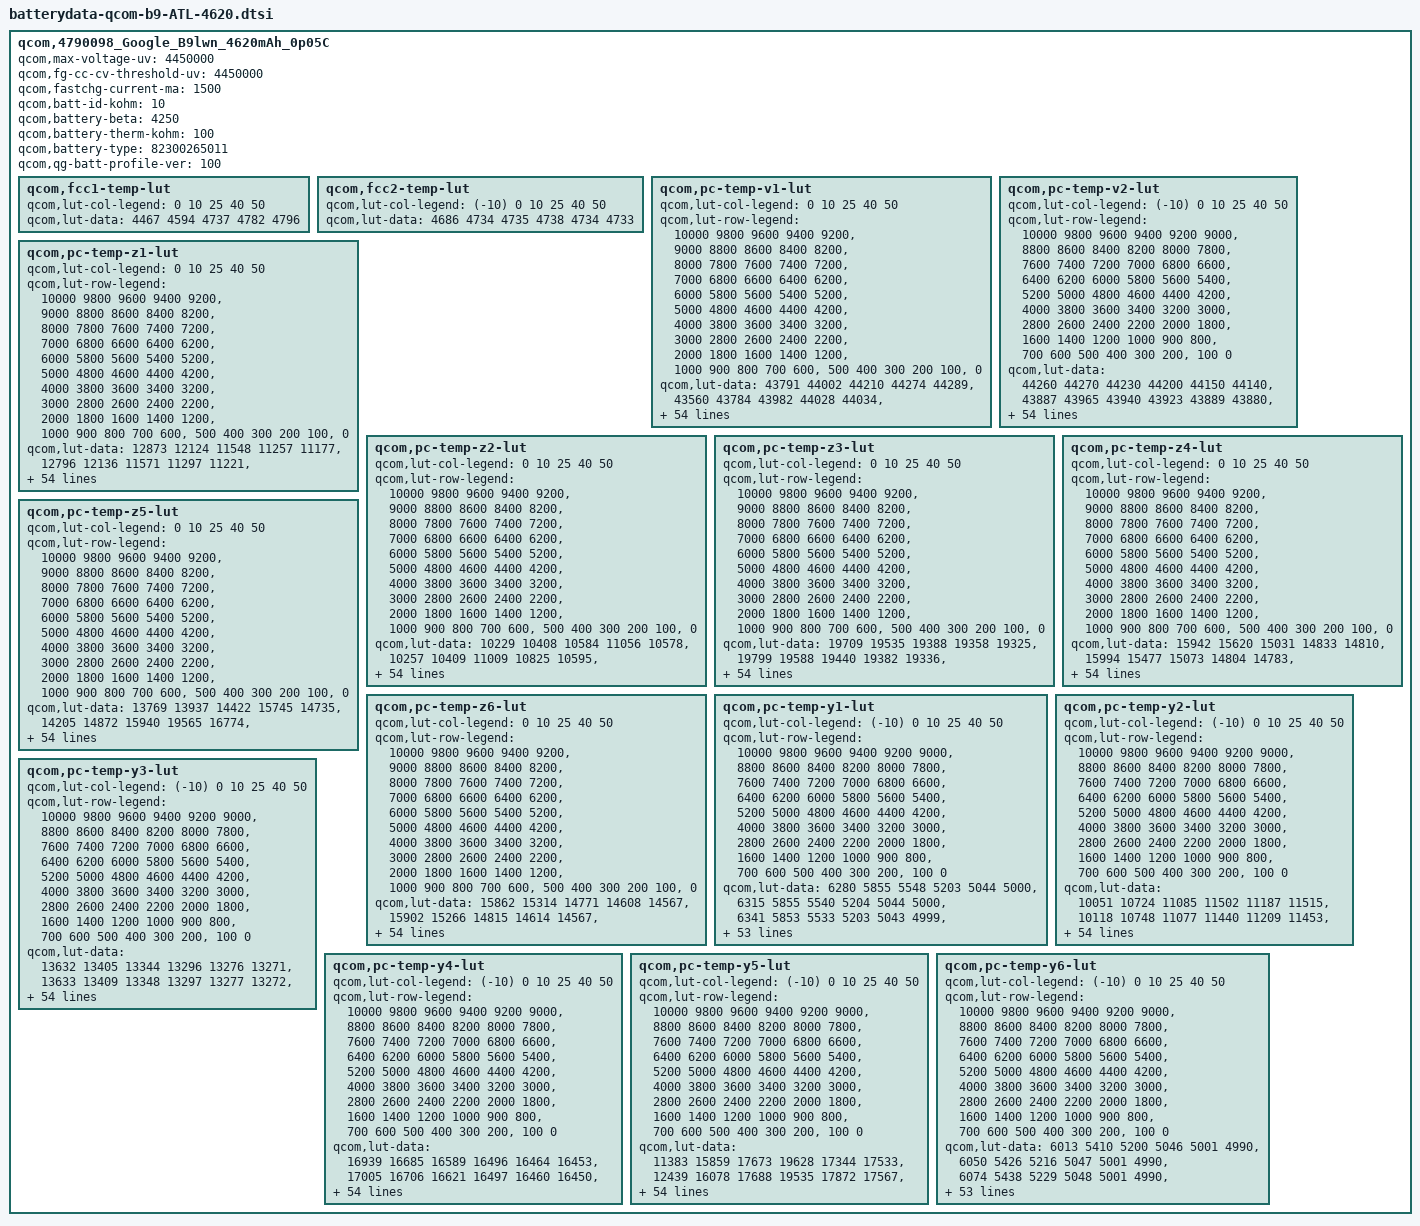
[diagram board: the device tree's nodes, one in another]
// SPDX-License-Identifier: GPL-2.0
qcom,4790098_Google_B9lwn_4620mAh_0p05C {
	/* 4790098_Google_B9lwn_4620mAh_0p05C_Oct30th2020 */
	qcom,max-voltage-uv = <4450000>;
	qcom,fg-cc-cv-threshold-uv = <4450000>;
	qcom,fastchg-current-ma = <1500>;
	qcom,batt-id-kohm = <10>;
	qcom,battery-beta = <4250>;
	qcom,battery-therm-kohm = <100>;
	qcom,battery-type = "82300265011";
	qcom,qg-batt-profile-ver = <100>;

	qcom,fcc1-temp-lut {
		qcom,lut-col-legend = <0 10 25 40 50>;
		qcom,lut-data = <4467 4594 4737 4782 4796>;
	};

	qcom,fcc2-temp-lut {
		qcom,lut-col-legend = <(-10) 0 10 25 40 50>;
		qcom,lut-data = <4686 4734 4735 4738 4734 4733>;
	};

	qcom,pc-temp-v1-lut {
		qcom,lut-col-legend = <0 10 25 40 50>;
		qcom,lut-row-legend = <10000 9800 9600 9400 9200>,
			<9000 8800 8600 8400 8200>,
			<8000 7800 7600 7400 7200>,
			<7000 6800 6600 6400 6200>,
			<6000 5800 5600 5400 5200>,
			<5000 4800 4600 4400 4200>,
			<4000 3800 3600 3400 3200>,
			<3000 2800 2600 2400 2200>,
			<2000 1800 1600 1400 1200>,
			<1000 900 800 700 600>,
			<500 400 300 200 100>,
			<0>;
		qcom,lut-data = <43791 44002 44210 44274 44289>,
			<43560 43784 43982 44028 44034>,
			<43330 43561 43754 43811 43813>,
			<43100 43333 43543 43600 43602>,
			<42867 43100 43323 43382 43390>,
			<42630 42864 43091 43154 43167>,
			<42396 42626 42854 42918 42936>,
			<42166 42387 42611 42680 42701>,
			<41939 42152 42363 42438 42461>,
			<41718 41919 42122 42196 42219>,
			<41503 41691 41886 41955 41980>,
			<41293 41467 41654 41716 41742>,
			<41089 41249 41427 41485 41510>,
			<40892 41045 41204 41259 41281>,
			<40694 40851 40988 41039 41059>,
			<40489 40657 40778 40824 40843>,
			<40290 40455 40577 40616 40633>,
			<40115 40260 40386 40418 40435>,
			<39957 40089 40202 40229 40246>,
			<39806 39937 40031 40050 40064>,
			<39660 39771 39870 39886 39898>,
			<39515 39576 39676 39709 39722>,
			<39357 39372 39396 39474 39497>,
			<39179 39164 39137 39224 39252>,
			<39007 38946 38993 39044 39064>,
			<38854 38794 38887 38904 38916>,
			<38714 38712 38785 38782 38787>,
			<38609 38648 38682 38671 38674>,
			<38530 38579 38588 38571 38571>,
			<38466 38510 38503 38477 38474>,
			<38415 38446 38426 38390 38383>,
			<38371 38384 38356 38312 38300>,
			<38332 38328 38294 38242 38224>,
			<38294 38278 38237 38178 38155>,
			<38259 38235 38187 38124 38093>,
			<38225 38193 38140 38074 38036>,
			<38196 38156 38093 38018 37971>,
			<38158 38117 38048 37957 37896>,
			<38096 38054 37989 37887 37813>,
			<38007 37957 37899 37802 37724>,
			<37904 37845 37790 37702 37624>,
			<37779 37722 37672 37587 37510>,
			<37633 37581 37536 37451 37376>,
			<37460 37410 37370 37291 37219>,
			<37338 37253 37209 37137 37068>,
			<37231 37149 37100 37038 36975>,
			<37191 37117 37077 37012 36952>,
			<37158 37096 37055 36996 36935>,
			<37124 37069 37038 36980 36918>,
			<37076 37031 37001 36939 36874>,
			<36905 36844 36806 36720 36631>,
			<36470 36417 36387 36297 36203>,
			<35896 35845 35822 35732 35637>,
			<35110 35059 35053 34965 34870>,
			<33811 33795 33864 33790 33691>,
			<30000 30000 30000 30000 30000>;
	};

	qcom,pc-temp-v2-lut {
		qcom,lut-col-legend = <(-10) 0 10 25 40 50>;
		qcom,lut-row-legend = <10000 9800 9600 9400 9200 9000>,
			<8800 8600 8400 8200 8000 7800>,
			<7600 7400 7200 7000 6800 6600>,
			<6400 6200 6000 5800 5600 5400>,
			<5200 5000 4800 4600 4400 4200>,
			<4000 3800 3600 3400 3200 3000>,
			<2800 2600 2400 2200 2000 1800>,
			<1600 1400 1200 1000 900 800>,
			<700 600 500 400 300 200>,
			<100 0>;
		qcom,lut-data = <44260 44270 44230 44200 44150 44140>,
			<43887 43965 43940 43923 43889 43880>,
			<43554 43685 43671 43662 43639 43632>,
			<43270 43433 43423 43421 43405 43398>,
			<43030 43209 43199 43199 43184 43178>,
			<42789 42981 42970 42972 42959 42955>,
			<42521 42737 42728 42734 42724 42721>,
			<42258 42490 42484 42492 42484 42483>,
			<42036 42244 42239 42251 42246 42246>,
			<41843 41999 41994 42010 42006 42008>,
			<41633 41765 41754 41773 41771 41774>,
			<41373 41547 41518 41541 41538 41543>,
			<41109 41332 41290 41314 41310 41316>,
			<40896 41110 41069 41090 41087 41094>,
			<40713 40887 40856 40870 40868 40876>,
			<40483 40664 40656 40660 40659 40666>,
			<40125 40444 40473 40457 40457 40462>,
			<39762 40217 40279 40262 40262 40265>,
			<39513 39963 40049 40082 40080 40083>,
			<39313 39699 39801 39905 39902 39904>,
			<39118 39469 39566 39698 39706 39713>,
			<38918 39265 39337 39453 39489 39506>,
			<38735 39078 39130 39222 39276 39299>,
			<38574 38904 38947 39020 39066 39088>,
			<38430 38743 38784 38840 38872 38888>,
			<38324 38592 38638 38693 38724 38739>,
			<38248 38451 38507 38570 38605 38619>,
			<38182 38319 38388 38460 38497 38510>,
			<38117 38186 38280 38360 38397 38408>,
			<38057 38074 38178 38266 38304 38313>,
			<37999 38006 38076 38180 38219 38227>,
			<37944 37957 37974 38099 38141 38147>,
			<37888 37909 37901 38025 38068 38073>,
			<37827 37861 37852 37959 38004 38008>,
			<37764 37814 37810 37895 37937 37938>,
			<37698 37765 37771 37829 37852 37841>,
			<37630 37713 37734 37763 37758 37723>,
			<37557 37653 37689 37688 37661 37614>,
			<37474 37583 37633 37605 37560 37511>,
			<37388 37505 37564 37519 37463 37414>,
			<37301 37416 37471 37437 37378 37328>,
			<37212 37312 37354 37345 37289 37238>,
			<37128 37185 37207 37219 37169 37116>,
			<37047 37031 37039 37074 37032 36977>,
			<36965 36888 36875 36926 36892 36842>,
			<36865 36797 36780 36872 36851 36804>,
			<36812 36762 36751 36854 36843 36794>,
			<36755 36731 36714 36837 36827 36779>,
			<36691 36695 36671 36807 36804 36756>,
			<36604 36637 36598 36737 36737 36680>,
			<36447 36464 36402 36515 36502 36420>,
			<36125 36017 35971 36052 36031 35942>,
			<35589 35358 35350 35435 35414 35327>,
			<34792 34428 34488 34597 34570 34476>,
			<33485 32895 33183 33372 33352 33229>,
			<31370 29553 29515 29517 29516 29515>;
	};

	qcom,pc-temp-z1-lut {
		qcom,lut-col-legend = <0 10 25 40 50>;
		qcom,lut-row-legend = <10000 9800 9600 9400 9200>,
			<9000 8800 8600 8400 8200>,
			<8000 7800 7600 7400 7200>,
			<7000 6800 6600 6400 6200>,
			<6000 5800 5600 5400 5200>,
			<5000 4800 4600 4400 4200>,
			<4000 3800 3600 3400 3200>,
			<3000 2800 2600 2400 2200>,
			<2000 1800 1600 1400 1200>,
			<1000 900 800 700 600>,
			<500 400 300 200 100>,
			<0>;
		qcom,lut-data = <12873 12124 11548 11257 11177>,
			<12796 12136 11571 11297 11221>,
			<12800 12142 11567 11298 11227>,
			<12806 12140 11567 11298 11229>,
			<12807 12133 11566 11298 11231>,
			<12801 12124 11563 11298 11231>,
			<12794 12114 11559 11296 11231>,
			<12788 12104 11555 11295 11230>,
			<12781 12104 11550 11293 11229>,
			<12773 12107 11547 11292 11228>,
			<12763 12108 11544 11291 11228>,
			<12756 12103 11543 11291 11228>,
			<12756 12097 11543 11291 11228>,
			<12757 12097 11543 11291 11229>,
			<12760 12098 11543 11292 11230>,
			<12768 12099 11542 11293 11231>,
			<12778 12096 11542 11294 11233>,
			<12780 12092 11543 11295 11234>,
			<12782 12093 11544 11296 11236>,
			<12782 12098 11546 11298 11238>,
			<12784 12103 11549 11299 11239>,
			<12787 12111 11552 11300 11241>,
			<12790 12118 11557 11303 11243>,
			<12799 12121 11562 11306 11245>,
			<12806 12123 11566 11310 11248>,
			<12806 12125 11570 11313 11252>,
			<12804 12128 11574 11317 11255>,
			<12805 12130 11579 11320 11258>,
			<12807 12132 11584 11324 11260>,
			<12810 12133 11588 11328 11263>,
			<12813 12135 11593 11331 11265>,
			<12817 12139 11597 11334 11268>,
			<12822 12143 11599 11336 11271>,
			<12835 12147 11602 11340 11273>,
			<12850 12150 11607 11343 11276>,
			<12856 12155 11613 11347 11278>,
			<12859 12163 11618 11350 11281>,
			<12860 12172 11623 11352 11284>,
			<12863 12177 11627 11355 11286>,
			<12868 12181 11632 11358 11288>,
			<12872 12184 11637 11362 11290>,
			<12876 12186 11641 11365 11292>,
			<12878 12188 11646 11368 11294>,
			<12877 12206 11650 11371 11296>,
			<12888 12210 11656 11374 11299>,
			<12884 12212 11664 11376 11300>,
			<12897 12204 11669 11376 11301>,
			<12890 12210 11670 11376 11300>,
			<12881 12212 11666 11377 11301>,
			<12897 12208 11668 11380 11302>,
			<12898 12219 11676 11385 11306>,
			<12943 12229 11687 11392 11313>,
			<12966 12258 11704 11401 11320>,
			<12979 12280 11722 11415 11332>,
			<12979 12280 11722 11415 11332>,
			<12979 12280 11722 11415 11332>;
	};

	qcom,pc-temp-z2-lut {
		qcom,lut-col-legend = <0 10 25 40 50>;
		qcom,lut-row-legend = <10000 9800 9600 9400 9200>,
			<9000 8800 8600 8400 8200>,
			<8000 7800 7600 7400 7200>,
			<7000 6800 6600 6400 6200>,
			<6000 5800 5600 5400 5200>,
			<5000 4800 4600 4400 4200>,
			<4000 3800 3600 3400 3200>,
			<3000 2800 2600 2400 2200>,
			<2000 1800 1600 1400 1200>,
			<1000 900 800 700 600>,
			<500 400 300 200 100>,
			<0>;
		qcom,lut-data = <10229 10408 10584 11056 10578>,
			<10257 10409 11009 10825 10595>,
			<10246 10399 10644 10790 10784>,
			<10231 10378 10614 10757 10774>,
			<10227 10338 10579 10717 10750>,
			<10228 10304 10529 10692 10700>,
			<10229 10277 10496 10672 10618>,
			<10221 10259 10506 10666 10578>,
			<10208 10265 10532 10666 10527>,
			<10207 10290 10583 10665 10487>,
			<10248 10310 10763 10660 10498>,
			<10287 10320 10877 10653 10526>,
			<10271 10331 10868 10624 10532>,
			<10218 10381 10856 10549 10538>,
			<10187 10492 10861 10515 10543>,
			<10179 10539 10879 10515 10549>,
			<10174 10481 10897 10520 10559>,
			<10179 10415 10923 10538 10568>,
			<10201 10410 10945 10572 10579>,
			<10222 10416 10879 10583 10591>,
			<10233 10421 10683 10581 10600>,
			<10242 10436 10608 10580 10613>,
			<10252 10451 10625 10612 10666>,
			<10263 10447 10640 10680 10745>,
			<10272 10423 10636 10760 10760>,
			<10279 10410 10629 10871 10746>,
			<10284 10420 10637 10918 10723>,
			<10290 10433 10668 10805 10607>,
			<10298 10439 10690 10669 10472>,
			<10306 10441 10663 10646 10458>,
			<10311 10444 10614 10638 10462>,
			<10316 10446 10606 10639 10468>,
			<10321 10449 10615 10660 10485>,
			<10328 10455 10627 10681 10510>,
			<10336 10467 10648 10689 10551>,
			<10344 10477 10673 10701 10613>,
			<10351 10482 10687 10735 10675>,
			<10359 10487 10701 10843 10747>,
			<10370 10499 10717 10904 10796>,
			<10380 10524 10760 10892 10819>,
			<10384 10538 10800 10876 10832>,
			<10385 10528 10795 10883 10829>,
			<10388 10520 10781 10906 10810>,
			<10406 10525 10786 10915 10784>,
			<10093 10580 10798 10900 10763>,
			<10065 10625 10798 10802 10772>,
			<10185 10615 10774 10771 10782>,
			<10204 10687 10748 10788 10749>,
			<10249 10688 10751 10766 10771>,
			<10228 10735 10787 10859 10915>,
			<10184 10812 10937 10783 10647>,
			<10040 10854 10929 10644 10484>,
			<9845 10811 10955 10586 10441>,
			<9628 10607 10892 10519 10441>,
			<9628 10607 10892 10519 10441>,
			<9628 10607 10892 10519 10441>;
	};

	qcom,pc-temp-z3-lut {
		qcom,lut-col-legend = <0 10 25 40 50>;
		qcom,lut-row-legend = <10000 9800 9600 9400 9200>,
			<9000 8800 8600 8400 8200>,
			<8000 7800 7600 7400 7200>,
			<7000 6800 6600 6400 6200>,
			<6000 5800 5600 5400 5200>,
			<5000 4800 4600 4400 4200>,
			<4000 3800 3600 3400 3200>,
			<3000 2800 2600 2400 2200>,
			<2000 1800 1600 1400 1200>,
			<1000 900 800 700 600>,
			<500 400 300 200 100>,
			<0>;
		qcom,lut-data = <19709 19535 19388 19358 19325>,
			<19799 19588 19440 19382 19336>,
			<19825 19626 19483 19392 19371>,
			<19839 19645 19492 19403 19381>,
			<19838 19659 19494 19407 19385>,
			<19828 19662 19490 19405 19383>,
			<19817 19658 19484 19401 19375>,
			<19808 19650 19478 19396 19369>,
			<19800 19639 19472 19389 19364>,
			<19796 19620 19469 19384 19360>,
			<19801 19606 19469 19382 19357>,
			<19805 19599 19467 19380 19354>,
			<19792 19593 19459 19375 19351>,
			<19767 19590 19448 19363 19346>,
			<19756 19585 19444 19358 19344>,
			<19763 19582 19442 19357 19343>,
			<19771 19576 19440 19356 19342>,
			<19767 19570 19437 19354 19339>,
			<19744 19565 19434 19352 19333>,
			<19731 19561 19428 19350 19330>,
			<19731 19559 19418 19349 19328>,
			<19732 19568 19415 19348 19327>,
			<19735 19579 19433 19349 19328>,
			<19753 19583 19450 19352 19332>,
			<19767 19586 19441 19360 19341>,
			<19767 19586 19418 19382 19363>,
			<19766 19578 19414 19393 19376>,
			<19765 19568 19439 19393 19369>,
			<19762 19568 19458 19392 19360>,
			<19756 19572 19459 19390 19356>,
			<19750 19575 19459 19386 19354>,
			<19742 19576 19457 19382 19351>,
			<19735 19577 19450 19377 19347>,
			<19730 19575 19442 19372 19343>,
			<19726 19570 19438 19365 19338>,
			<19721 19564 19434 19359 19334>,
			<19714 19561 19431 19357 19333>,
			<19708 19557 19429 19357 19333>,
			<19702 19552 19425 19357 19333>,
			<19695 19546 19420 19354 19335>,
			<19688 19540 19416 19350 19336>,
			<19681 19535 19412 19350 19336>,
			<19671 19530 19408 19351 19334>,
			<19657 19524 19406 19351 19334>,
			<19352 19500 19400 19350 19335>,
			<19264 19479 19394 19341 19328>,
			<19263 19474 19385 19340 19323>,
			<19262 19447 19387 19336 19321>,
			<19262 19445 19379 19331 19317>,
			<19262 19435 19373 19326 19309>,
			<19262 19417 19343 19339 19335>,
			<19263 19375 19346 19346 19340>,
			<19265 19337 19340 19349 19343>,
			<19272 19340 19334 19351 19332>,
			<19272 19340 19334 19351 19332>,
			<19272 19340 19334 19351 19332>;
	};

	qcom,pc-temp-z4-lut {
		qcom,lut-col-legend = <0 10 25 40 50>;
		qcom,lut-row-legend = <10000 9800 9600 9400 9200>,
			<9000 8800 8600 8400 8200>,
			<8000 7800 7600 7400 7200>,
			<7000 6800 6600 6400 6200>,
			<6000 5800 5600 5400 5200>,
			<5000 4800 4600 4400 4200>,
			<4000 3800 3600 3400 3200>,
			<3000 2800 2600 2400 2200>,
			<2000 1800 1600 1400 1200>,
			<1000 900 800 700 600>,
			<500 400 300 200 100>,
			<0>;
		qcom,lut-data = <15942 15620 15031 14833 14810>,
			<15994 15477 15073 14804 14783>,
			<15856 15348 15121 14906 14835>,
			<15631 15233 15024 14873 14815>,
			<15485 15129 14950 14832 14786>,
			<15381 15047 14900 14805 14769>,
			<15293 14982 14861 14782 14756>,
			<15219 14932 14834 14769 14747>,
			<15154 14898 14814 14762 14741>,
			<15085 14873 14793 14755 14736>,
			<14997 14855 14769 14744 14729>,
			<14933 14841 14753 14734 14722>,
			<14923 14830 14747 14729 14715>,
			<14923 14813 14742 14726 14709>,
			<14920 14791 14735 14722 14702>,
			<14910 14783 14725 14713 14693>,
			<14898 14792 14716 14702 14684>,
			<14887 14802 14710 14694 14679>,
			<14878 14796 14706 14687 14674>,
			<14867 14775 14706 14684 14671>,
			<14850 14765 14713 14682 14669>,
			<14834 14786 14730 14682 14668>,
			<14833 14824 14823 14738 14708>,
			<14855 14876 14908 14829 14786>,
			<14884 14952 14912 14838 14798>,
			<14917 14985 14912 14807 14766>,
			<14953 14965 14905 14778 14740>,
			<14964 14930 14861 14759 14731>,
			<14957 14903 14816 14743 14725>,
			<14947 14877 14794 14730 14716>,
			<14935 14858 14779 14719 14705>,
			<14919 14845 14771 14712 14696>,
			<14904 14835 14766 14705 14689>,
			<14891 14829 14763 14702 14684>,
			<14879 14825 14761 14702 14682>,
			<14866 14821 14760 14702 14681>,
			<14853 14815 14761 14704 14683>,
			<14842 14810 14764 14716 14700>,
			<14835 14810 14768 14726 14711>,
			<14830 14811 14774 14731 14710>,
			<14823 14811 14779 14735 14709>,
			<14811 14796 14772 14731 14705>,
			<14798 14775 14755 14718 14698>,
			<14783 14763 14747 14717 14700>,
			<15008 14736 14732 14715 14700>,
			<15074 14713 14704 14698 14686>,
			<15070 14706 14695 14687 14680>,
			<15059 14719 14675 14670 14661>,
			<15052 14708 14664 14653 14645>,
			<15043 14711 14665 14654 14647>,
			<15040 14742 14720 14666 14648>,
			<15065 14798 14722 14664 14649>,
			<15079 14848 14727 14662 14646>,
			<15095 14855 14735 14659 14655>,
			<15095 14855 14735 14659 14655>,
			<15095 14855 14735 14659 14655>;
	};

	qcom,pc-temp-z5-lut {
		qcom,lut-col-legend = <0 10 25 40 50>;
		qcom,lut-row-legend = <10000 9800 9600 9400 9200>,
			<9000 8800 8600 8400 8200>,
			<8000 7800 7600 7400 7200>,
			<7000 6800 6600 6400 6200>,
			<6000 5800 5600 5400 5200>,
			<5000 4800 4600 4400 4200>,
			<4000 3800 3600 3400 3200>,
			<3000 2800 2600 2400 2200>,
			<2000 1800 1600 1400 1200>,
			<1000 900 800 700 600>,
			<500 400 300 200 100>,
			<0>;
		qcom,lut-data = <13769 13937 14422 15745 14735>,
			<14205 14872 15940 19565 16774>,
			<14536 15721 16960 17400 19051>,
			<14820 16480 17521 17969 19995>,
			<15074 17175 17860 18699 20665>,
			<15292 17791 18020 19247 20802>,
			<15522 18365 18199 19711 20611>,
			<15775 18882 18683 19752 20520>,
			<16064 19301 19433 19425 20215>,
			<16552 19654 20066 19212 19942>,
			<17869 20037 20971 19566 19979>,
			<18956 20560 21433 20064 20073>,
			<18916 21053 21107 19848 20079>,
			<18614 21354 20676 18841 19994>,
			<18532 21662 20801 18415 20052>,
			<19891 21970 21710 18923 20906>,
			<21491 22261 22603 19670 21848>,
			<21535 22641 23303 20269 21752>,
			<20884 23364 23874 20887 21230>,
			<20497 24796 23954 21506 21085>,
			<21485 26775 23577 22226 21659>,
			<23767 30962 24094 22617 22158>,
			<26985 34842 28694 21626 20740>,
			<33112 34888 32871 19894 18012>,
			<37370 33324 29352 19185 17583>,
			<37343 31393 20912 18780 18564>,
			<36911 28067 18577 18646 19155>,
			<36289 24975 19919 19190 18977>,
			<34974 24775 21742 20178 18744>,
			<33411 25593 23631 21308 19013>,
			<32110 26690 25688 22763 20146>,
			<30838 28621 27255 24174 21264>,
			<30319 30763 28500 25654 22243>,
			<30403 31888 29674 26771 23214>,
			<30544 32725 31155 27349 24337>,
			<30639 33187 32333 27742 25400>,
			<30680 33428 32376 27800 25521>,
			<30687 33605 31956 27577 24819>,
			<30989 33408 31266 27176 24086>,
			<31566 32385 29039 24979 23611>,
			<31628 31583 26728 22403 23162>,
			<30489 31141 26062 22280 22692>,
			<29377 30707 25788 22680 22136>,
			<28675 29581 24921 22288 21243>,
			<15248 28263 24708 21295 20815>,
			<11406 25940 26217 20665 19721>,
			<11359 24957 24158 21492 19074>,
			<11313 19456 26643 22131 20636>,
			<11300 19479 25029 24107 23792>,
			<11304 18406 23592 22828 20600>,
			<11335 16640 15872 20107 23712>,
			<11275 14017 15213 20168 23285>,
			<11209 12528 14458 20074 23609>,
			<11246 12446 13876 19838 18287>,
			<11246 12446 13876 19838 18287>,
			<11246 12446 13876 19838 18287>;
	};

	qcom,pc-temp-z6-lut {
		qcom,lut-col-legend = <0 10 25 40 50>;
		qcom,lut-row-legend = <10000 9800 9600 9400 9200>,
			<9000 8800 8600 8400 8200>,
			<8000 7800 7600 7400 7200>,
			<7000 6800 6600 6400 6200>,
			<6000 5800 5600 5400 5200>,
			<5000 4800 4600 4400 4200>,
			<4000 3800 3600 3400 3200>,
			<3000 2800 2600 2400 2200>,
			<2000 1800 1600 1400 1200>,
			<1000 900 800 700 600>,
			<500 400 300 200 100>,
			<0>;
		qcom,lut-data = <15862 15314 14771 14608 14567>,
			<15902 15266 14815 14614 14567>,
			<15835 15218 14855 14661 14609>,
			<15722 15170 14819 14652 14604>,
			<15640 15122 14787 14639 14597>,
			<15574 15079 14762 14627 14589>,
			<15516 15040 14741 14615 14579>,
			<15467 15007 14725 14606 14572>,
			<15425 14980 14712 14599 14566>,
			<15385 14957 14700 14592 14561>,
			<15345 14941 14690 14587 14557>,
			<15314 14930 14682 14581 14552>,
			<15296 14921 14674 14575 14547>,
			<15284 14910 14667 14568 14542>,
			<15279 14899 14660 14563 14537>,
			<15279 14894 14655 14558 14533>,
			<15278 14894 14650 14553 14529>,
			<15274 14893 14645 14549 14525>,
			<15260 14889 14642 14545 14520>,
			<15249 14878 14641 14543 14517>,
			<15244 14873 14640 14542 14515>,
			<15241 14888 14643 14541 14514>,
			<15244 14913 14692 14567 14534>,
			<15265 14941 14741 14609 14571>,
			<15290 14978 14739 14616 14579>,
			<15309 14993 14730 14614 14578>,
			<15326 14981 14723 14612 14576>,
			<15331 14964 14717 14605 14570>,
			<15329 14953 14711 14597 14562>,
			<15326 14945 14705 14590 14556>,
			<15321 14940 14699 14584 14550>,
			<15313 14937 14693 14579 14545>,
			<15307 14935 14688 14574 14540>,
			<15301 14933 14684 14569 14535>,
			<15297 14930 14682 14566 14532>,
			<15293 14928 14681 14563 14529>,
			<15289 14927 14681 14563 14530>,
			<15287 14926 14682 14569 14537>,
			<15288 14927 14682 14573 14542>,
			<15291 14928 14683 14574 14543>,
			<15291 14929 14685 14574 14543>,
			<15291 14923 14682 14572 14542>,
			<15289 14916 14674 14568 14538>,
			<15284 14914 14671 14569 14540>,
			<15244 14900 14664 14568 14541>,
			<15236 14885 14651 14555 14531>,
			<15236 14881 14644 14551 14525>,
			<15233 14875 14636 14541 14517>,
			<15234 14872 14628 14530 14507>,
			<15238 14872 14627 14530 14504>,
			<15246 14883 14638 14543 14519>,
			<15272 14893 14644 14547 14524>,
			<15297 14905 14647 14550 14527>,
			<15337 14927 14654 14553 14528>,
			<15337 14927 14654 14553 14528>,
			<15337 14927 14654 14553 14528>;
	};

	qcom,pc-temp-y1-lut {
		qcom,lut-col-legend = <(-10) 0 10 25 40 50>;
		qcom,lut-row-legend = <10000 9800 9600 9400 9200 9000>,
			<8800 8600 8400 8200 8000 7800>,
			<7600 7400 7200 7000 6800 6600>,
			<6400 6200 6000 5800 5600 5400>,
			<5200 5000 4800 4600 4400 4200>,
			<4000 3800 3600 3400 3200 3000>,
			<2800 2600 2400 2200 2000 1800>,
			<1600 1400 1200 1000 900 800>,
			<700 600 500 400 300 200>,
			<100 0>;
		qcom,lut-data = <6280 5855 5548 5203 5044 5000>,
			<6315 5855 5540 5204 5044 5000>,
			<6341 5853 5533 5203 5043 4999>,
			<6359 5851 5527 5201 5042 4998>,
			<6369 5849 5522 5200 5041 4997>,
			<6372 5849 5521 5197 5040 4996>,
			<6362 5850 5523 5194 5038 4995>,
			<6349 5851 5525 5191 5036 4994>,
			<6350 5849 5524 5188 5035 4994>,
			<6359 5843 5517 5186 5035 4994>,
			<6363 5841 5512 5184 5035 4994>,
			<6363 5840 5507 5181 5033 4994>,
			<6362 5840 5504 5180 5032 4994>,
			<6362 5843 5503 5179 5031 4994>,
			<6365 5850 5503 5179 5031 4994>,
			<6366 5854 5504 5179 5031 4994>,
			<6360 5857 5506 5179 5031 4994>,
			<6353 5859 5509 5179 5032 4995>,
			<6352 5863 5510 5180 5032 4995>,
			<6352 5869 5510 5181 5033 4996>,
			<6354 5868 5512 5183 5034 4997>,
			<6367 5862 5516 5186 5035 4998>,
			<6380 5858 5518 5189 5037 4999>,
			<6380 5860 5519 5192 5037 5000>,
			<6376 5863 5521 5195 5038 5001>,
			<6374 5864 5522 5197 5040 5003>,
			<6367 5865 5523 5200 5042 5003>,
			<6362 5865 5524 5202 5045 5005>,
			<6365 5867 5526 5205 5047 5006>,
			<6368 5869 5529 5209 5049 5008>,
			<6367 5868 5531 5212 5051 5010>,
			<6356 5866 5533 5215 5052 5012>,
			<6349 5865 5535 5219 5055 5014>,
			<6350 5866 5536 5223 5058 5016>,
			<6352 5868 5538 5227 5061 5018>,
			<6359 5874 5541 5230 5063 5019>,
			<6380 5884 5544 5233 5066 5020>,
			<6392 5885 5548 5236 5067 5021>,
			<6382 5877 5553 5240 5068 5023>,
			<6367 5870 5556 5242 5069 5024>,
			<6365 5871 5555 5243 5071 5025>,
			<6366 5872 5554 5244 5072 5025>,
			<6376 5883 5552 5249 5073 5027>,
			<6388 5890 5554 5253 5075 5028>,
			<6367 5905 5564 5257 5077 5030>,
			<6375 5895 5569 5265 5079 5031>,
			<6398 5906 5566 5263 5080 5032>,
			<6427 5904 5567 5264 5081 5032>,
			<6447 5918 5564 5267 5081 5033>,
			<6512 5931 5568 5271 5081 5032>,
			<6555 5936 5575 5280 5082 5034>,
			<6628 5980 5585 5289 5087 5038>,
			<6755 6051 5618 5296 5092 5042>,
			<6815 6277 5660 5314 5100 5048>,
			<6815 6277 5660 5314 5100 5048>,
			<6815 6277 5660 5314 5100 5048>;
	};

	qcom,pc-temp-y2-lut {
		qcom,lut-col-legend = <(-10) 0 10 25 40 50>;
		qcom,lut-row-legend = <10000 9800 9600 9400 9200 9000>,
			<8800 8600 8400 8200 8000 7800>,
			<7600 7400 7200 7000 6800 6600>,
			<6400 6200 6000 5800 5600 5400>,
			<5200 5000 4800 4600 4400 4200>,
			<4000 3800 3600 3400 3200 3000>,
			<2800 2600 2400 2200 2000 1800>,
			<1600 1400 1200 1000 900 800>,
			<700 600 500 400 300 200>,
			<100 0>;
		qcom,lut-data = <10051 10724 11085 11502 11187 11515>,
			<10118 10748 11077 11440 11209 11453>,
			<10195 10772 11066 11374 11222 11360>,
			<10272 10792 11052 11312 11228 11262>,
			<10334 10806 11036 11261 11229 11182>,
			<10372 10811 11022 11226 11226 11146>,
			<10386 10805 11005 11203 11174 11139>,
			<10398 10798 10989 11187 11113 11134>,
			<10461 10800 10974 11180 11109 11117>,
			<10627 10809 10959 11175 11119 11078>,
			<10706 10813 10955 11173 11133 11059>,
			<10662 10809 10968 11175 11169 11062>,
			<10611 10805 10988 11181 11205 11067>,
			<10628 10867 11012 11197 11209 11073>,
			<10697 11009 11043 11230 11205 11085>,
			<10704 11047 11081 11266 11214 11089>,
			<10227 11014 11134 11304 11266 11092>,
			<9729 10988 11178 11345 11336 11105>,
			<9692 11008 11198 11398 11418 11179>,
			<9688 11048 11212 11451 11510 11316>,
			<9683 11073 11220 11454 11568 11434>,
			<9678 11091 11226 11420 11614 11564>,
			<9674 11103 11231 11399 11633 11624>,
			<9672 11111 11241 11396 11547 11530>,
			<9671 11115 11253 11395 11428 11403>,
			<9670 11101 11267 11405 11424 11390>,
			<9669 11045 11283 11443 11476 11411>,
			<9668 11019 11288 11478 11528 11439>,
			<9667 11044 11270 11503 11576 11491>,
			<9666 11071 11250 11526 11618 11542>,
			<9665 11057 11250 11551 11641 11562>,
			<9665 10991 11253 11576 11657 11573>,
			<9664 10856 11252 11588 11685 11591>,
			<9664 10320 11222 11593 11759 11631>,
			<9663 9844 11181 11593 11815 11660>,
			<9663 9761 11149 11581 11762 11656>,
			<9663 9719 11115 11556 11648 11642>,
			<9663 9698 11069 11533 11596 11621>,
			<9662 9686 11003 11508 11568 11581>,
			<9662 9679 10921 11485 11548 11549>,
			<9662 9674 10831 11469 11535 11538>,
			<9661 9671 10685 11450 11525 11532>,
			<9661 9668 10160 11401 11521 11537>,
			<9660 9665 9834 11359 11535 11531>,
			<9659 9665 9844 11338 11521 11507>,
			<9658 9663 9724 11283 11415 11322>,
			<9657 9661 9700 11252 11374 11261>,
			<9655 9660 9685 11242 11344 11245>,
			<9653 9658 9675 11226 11392 11287>,
			<9652 9657 9669 11219 11361 11214>,
			<9650 9654 9664 11148 11370 11155>,
			<9649 9651 9660 11056 11306 11125>,
			<9649 9649 9656 10963 11179 11028>,
			<9649 9650 9652 10849 11054 10903>,
			<9649 9650 9652 10849 11054 10903>,
			<9649 9650 9652 10849 11054 10903>;
	};

	qcom,pc-temp-y3-lut {
		qcom,lut-col-legend = <(-10) 0 10 25 40 50>;
		qcom,lut-row-legend = <10000 9800 9600 9400 9200 9000>,
			<8800 8600 8400 8200 8000 7800>,
			<7600 7400 7200 7000 6800 6600>,
			<6400 6200 6000 5800 5600 5400>,
			<5200 5000 4800 4600 4400 4200>,
			<4000 3800 3600 3400 3200 3000>,
			<2800 2600 2400 2200 2000 1800>,
			<1600 1400 1200 1000 900 800>,
			<700 600 500 400 300 200>,
			<100 0>;
		qcom,lut-data = <13632 13405 13344 13296 13276 13271>,
			<13633 13409 13348 13297 13277 13272>,
			<13634 13414 13352 13298 13279 13273>,
			<13634 13419 13356 13299 13280 13274>,
			<13634 13423 13360 13301 13281 13274>,
			<13633 13424 13362 13301 13283 13275>,
			<13624 13424 13364 13302 13284 13276>,
			<13613 13423 13365 13302 13285 13277>,
			<13614 13423 13366 13302 13286 13278>,
			<13624 13422 13367 13302 13287 13280>,
			<13628 13423 13367 13302 13288 13281>,
			<13569 13428 13365 13304 13288 13283>,
			<13499 13434 13362 13306 13288 13284>,
			<13497 13426 13360 13306 13288 13285>,
			<13512 13409 13357 13305 13287 13285>,
			<13518 13404 13357 13305 13287 13285>,
			<13510 13407 13358 13306 13289 13284>,
			<13502 13410 13359 13306 13291 13283>,
			<13500 13403 13356 13307 13291 13284>,
			<13501 13391 13350 13308 13291 13285>,
			<13501 13383 13345 13307 13291 13285>,
			<13501 13379 13341 13305 13290 13285>,
			<13501 13375 13337 13301 13288 13284>,
			<13500 13370 13335 13297 13284 13280>,
			<13499 13366 13332 13294 13280 13276>,
			<13500 13363 13330 13293 13279 13276>,
			<13524 13361 13328 13293 13278 13276>,
			<13555 13357 13327 13293 13278 13276>,
			<13584 13344 13325 13293 13278 13275>,
			<13615 13332 13323 13294 13279 13275>,
			<13652 13333 13321 13294 13279 13275>,
			<13696 13337 13319 13294 13279 13275>,
			<13741 13341 13319 13295 13279 13275>,
			<13785 13348 13320 13294 13280 13275>,
			<13829 13357 13323 13294 13281 13276>,
			<13871 13371 13325 13294 13280 13276>,
			<13913 13392 13329 13295 13279 13274>,
			<13952 13413 13332 13294 13278 13274>,
			<13988 13436 13335 13293 13277 13274>,
			<14021 13464 13338 13292 13277 13274>,
			<14054 13498 13342 13293 13277 13275>,
			<14086 13540 13346 13295 13277 13276>,
			<14128 13592 13349 13295 13278 13276>,
			<14183 13634 13359 13294 13277 13274>,
			<14231 13622 13353 13292 13274 13272>,
			<14317 13734 13392 13295 13277 13275>,
			<14461 13812 13420 13297 13281 13278>,
			<14756 13922 13455 13302 13283 13281>,
			<15238 14070 13515 13306 13288 13284>,
			<16124 14302 13595 13311 13289 13284>,
			<17968 14816 13717 13312 13287 13280>,
			<22338 16156 13932 13314 13286 13280>,
			<34140 19995 14408 13322 13287 13283>,
			<64883 34388 15534 13333 13290 13285>,
			<64883 34388 15534 13333 13290 13285>,
			<64883 34388 15534 13333 13290 13285>;
	};

	qcom,pc-temp-y4-lut {
		qcom,lut-col-legend = <(-10) 0 10 25 40 50>;
		qcom,lut-row-legend = <10000 9800 9600 9400 9200 9000>,
			<8800 8600 8400 8200 8000 7800>,
			<7600 7400 7200 7000 6800 6600>,
			<6400 6200 6000 5800 5600 5400>,
			<5200 5000 4800 4600 4400 4200>,
			<4000 3800 3600 3400 3200 3000>,
			<2800 2600 2400 2200 2000 1800>,
			<1600 1400 1200 1000 900 800>,
			<700 600 500 400 300 200>,
			<100 0>;
		qcom,lut-data = <16939 16685 16589 16496 16464 16453>,
			<17005 16706 16621 16497 16460 16450>,
			<17097 16753 16659 16499 16457 16448>,
			<17189 16808 16695 16500 16455 16447>,
			<17260 16852 16720 16501 16453 16446>,
			<17286 16867 16728 16502 16453 16446>,
			<17278 16867 16722 16503 16453 16446>,
			<17263 16866 16713 16504 16454 16447>,
			<17244 16866 16709 16507 16456 16448>,
			<17216 16867 16706 16513 16458 16449>,
			<17206 16869 16705 16519 16462 16450>,
			<17283 16872 16714 16523 16466 16452>,
			<17373 16878 16728 16528 16472 16455>,
			<17366 16905 16745 16537 16479 16459>,
			<17307 16954 16768 16551 16489 16465>,
			<17236 16965 16790 16565 16497 16472>,
			<17141 16938 16815 16582 16504 16481>,
			<17049 16899 16828 16601 16513 16491>,
			<16993 16846 16805 16625 16530 16503>,
			<16952 16785 16753 16647 16550 16515>,
			<16909 16747 16708 16643 16553 16517>,
			<16857 16724 16665 16596 16543 16516>,
			<16815 16703 16631 16551 16528 16513>,
			<16793 16682 16607 16517 16496 16487>,
			<16778 16661 16590 16492 16463 16454>,
			<16774 16636 16579 16490 16459 16450>,
			<16774 16607 16572 16490 16461 16451>,
			<16774 16587 16565 16491 16463 16452>,
			<16775 16576 16561 16495 16469 16457>,
			<16776 16570 16556 16502 16476 16464>,
			<16776 16571 16541 16508 16485 16472>,
			<16773 16580 16515 16515 16495 16482>,
			<16771 16592 16508 16522 16504 16491>,
			<16774 16623 16514 16530 16514 16501>,
			<16779 16655 16525 16536 16519 16508>,
			<16780 16673 16542 16533 16513 16499>,
			<16779 16686 16565 16524 16498 16478>,
			<16778 16697 16588 16514 16485 16467>,
			<16777 16706 16615 16497 16470 16461>,
			<16776 16710 16633 16488 16462 16459>,
			<16777 16709 16636 16493 16465 16460>,
			<16780 16705 16640 16498 16468 16461>,
			<16785 16685 16646 16501 16465 16456>,
			<16791 16665 16646 16502 16460 16451>,
			<16783 16640 16610 16477 16444 16436>,
			<16764 16641 16626 16485 16452 16443>,
			<16788 16653 16642 16500 16459 16451>,
			<16867 16665 16665 16517 16469 16462>,
			<16983 16687 16695 16536 16484 16485>,
			<17194 16724 16740 16557 16498 16496>,
			<17607 16797 16766 16549 16475 16463>,
			<18687 17004 16769 16536 16451 16446>,
			<24328 18062 16881 16560 16457 16448>,
			<65535 29931 17687 16605 16475 16461>,
			<65535 29931 17687 16605 16475 16461>,
			<65535 29931 17687 16605 16475 16461>;
	};

	qcom,pc-temp-y5-lut {
		qcom,lut-col-legend = <(-10) 0 10 25 40 50>;
		qcom,lut-row-legend = <10000 9800 9600 9400 9200 9000>,
			<8800 8600 8400 8200 8000 7800>,
			<7600 7400 7200 7000 6800 6600>,
			<6400 6200 6000 5800 5600 5400>,
			<5200 5000 4800 4600 4400 4200>,
			<4000 3800 3600 3400 3200 3000>,
			<2800 2600 2400 2200 2000 1800>,
			<1600 1400 1200 1000 900 800>,
			<700 600 500 400 300 200>,
			<100 0>;
		qcom,lut-data = <11383 15859 17673 19628 17344 17533>,
			<12439 16078 17688 19535 17872 17567>,
			<13683 16297 17791 19279 18291 17536>,
			<14913 16487 17931 18906 18595 17464>,
			<15925 16621 18057 18460 18776 17376>,
			<16518 16668 18122 17984 18826 17295>,
			<16733 16636 18194 17416 18724 17191>,
			<16914 16580 18262 16787 18528 17073>,
			<17856 16533 18168 16114 18278 17201>,
			<20346 16472 17782 15400 17882 17818>,
			<21470 16507 17336 15134 17423 18093>,
			<19028 17462 16757 15197 16876 18322>,
			<16167 18382 16202 15254 16269 18395>,
			<17333 17909 15813 14960 15531 17879>,
			<21805 16748 15499 14396 14762 17017>,
			<23507 16816 15681 14246 14577 16192>,
			<19420 20355 17983 14328 14691 15269>,
			<15192 23097 20252 14489 14821 14746>,
			<15157 22431 21094 15244 14905 14791>,
			<15720 21233 21678 16769 15034 14943>,
			<15900 21079 22219 18629 15888 15706>,
			<15598 21636 22739 21297 19500 18798>,
			<15078 22241 23078 22590 21654 20692>,
			<14095 22666 23269 21657 21061 20742>,
			<12727 23101 23402 20341 20030 20729>,
			<12344 23766 23444 19953 19298 20529>,
			<12343 24707 23404 19774 18655 19829>,
			<12344 24929 23398 19736 18250 19025>,
			<12368 20141 23786 20111 17853 17967>,
			<12447 14902 24166 20648 17555 17059>,
			<12598 14643 23685 20984 17521 16778>,
			<12987 14921 22334 21263 17502 16618>,
			<13319 14976 21405 21636 17724 16628>,
			<13446 14442 20856 22200 18908 17306>,
			<13539 13966 20488 22851 20002 18037>,
			<13682 14101 20303 23800 20221 18319>,
			<13894 14432 20167 24848 20270 18545>,
			<13999 14582 19952 24769 20279 18695>,
			<13848 14633 19590 22842 20265 19012>,
			<13572 14675 19237 21188 20178 19378>,
			<13293 14719 19033 20713 19232 19749>,
			<12919 14773 18742 20238 18339 20000>,
			<12788 14899 16968 19068 18439 19906>,
			<12757 14291 15001 18170 18710 19830>,
			<12952 13429 14752 20412 18016 19524>,
			<13096 13434 14480 19895 16916 18050>,
			<12985 13279 14593 18587 18027 18360>,
			<12490 13421 14213 18371 17663 18863>,
			<12046 13632 14279 17869 19106 19420>,
			<11451 13755 14416 17890 18818 18106>,
			<10633 13150 14294 19107 19568 17751>,
			<9691 11191 14209 20524 22017 20110>,
			<9063 9852 13443 21031 21855 23042>,
			<8796 9010 10810 21378 23349 24706>,
			<8796 9010 10810 21378 23349 24706>,
			<8796 9010 10810 21378 23349 24706>;
	};

	qcom,pc-temp-y6-lut {
		qcom,lut-col-legend = <(-10) 0 10 25 40 50>;
		qcom,lut-row-legend = <10000 9800 9600 9400 9200 9000>,
			<8800 8600 8400 8200 8000 7800>,
			<7600 7400 7200 7000 6800 6600>,
			<6400 6200 6000 5800 5600 5400>,
			<5200 5000 4800 4600 4400 4200>,
			<4000 3800 3600 3400 3200 3000>,
			<2800 2600 2400 2200 2000 1800>,
			<1600 1400 1200 1000 900 800>,
			<700 600 500 400 300 200>,
			<100 0>;
		qcom,lut-data = <6013 5410 5200 5046 5001 4990>,
			<6050 5426 5216 5047 5001 4990>,
			<6074 5438 5229 5048 5001 4990>,
			<6088 5447 5238 5049 5001 4990>,
			<6094 5452 5243 5050 5002 4991>,
			<6095 5454 5245 5050 5002 4991>,
			<6085 5450 5241 5050 5003 4992>,
			<6071 5445 5235 5050 5004 4993>,
			<6067 5441 5232 5051 5006 4994>,
			<6066 5438 5229 5052 5007 4995>,
			<6064 5437 5227 5053 5009 4997>,
			<6046 5440 5227 5055 5010 4999>,
			<6026 5443 5227 5058 5012 5000>,
			<6023 5445 5228 5061 5014 5002>,
			<6022 5447 5232 5064 5016 5004>,
			<6018 5447 5237 5068 5018 5006>,
			<5966 5443 5245 5073 5021 5008>,
			<5910 5437 5250 5078 5025 5010>,
			<5897 5420 5241 5085 5031 5014>,
			<5891 5396 5222 5092 5036 5018>,
			<5886 5384 5206 5091 5037 5019>,
			<5882 5378 5191 5076 5032 5018>,
			<5879 5374 5181 5061 5026 5016>,
			<5880 5371 5174 5048 5014 5006>,
			<5884 5369 5169 5040 5002 4994>,
			<5892 5367 5166 5039 5001 4992>,
			<5916 5366 5165 5039 5001 4992>,
			<5945 5366 5164 5039 5002 4993>,
			<5972 5367 5165 5042 5004 4994>,
			<6001 5369 5165 5045 5006 4996>,
			<6032 5377 5163 5047 5009 4998>,
			<6068 5399 5159 5050 5012 5001>,
			<6104 5423 5159 5053 5015 5004>,
			<6139 5450 5166 5056 5019 5008>,
			<6174 5479 5178 5058 5021 5010>,
			<6208 5512 5192 5058 5020 5007>,
			<6243 5549 5211 5057 5015 5001>,
			<6275 5587 5233 5055 5010 4997>,
			<6305 5628 5259 5050 5006 4996>,
			<6334 5671 5286 5047 5003 4995>,
			<6364 5716 5314 5050 5004 4996>,
			<6395 5763 5344 5054 5006 4997>,
			<6434 5814 5375 5056 5005 4996>,
			<6484 5855 5408 5058 5004 4994>,
			<6528 5848 5391 5050 4997 4988>,
			<6602 5951 5464 5056 5002 4993>,
			<6742 6025 5513 5064 5007 4997>,
			<7040 6125 5572 5073 5011 5003>,
			<7494 6262 5655 5083 5020 5012>,
			<8286 6480 5758 5095 5024 5015>,
			<9846 6953 5888 5095 5016 5003>,
			<13359 8096 6088 5096 5009 4998>,
			<23003 11207 6543 5117 5012 5002>,
			<61588 24193 7688 5148 5020 5008>,
			<61588 24193 7688 5148 5020 5008>,
			<61588 24193 7688 5148 5020 5008>;
	};

};
